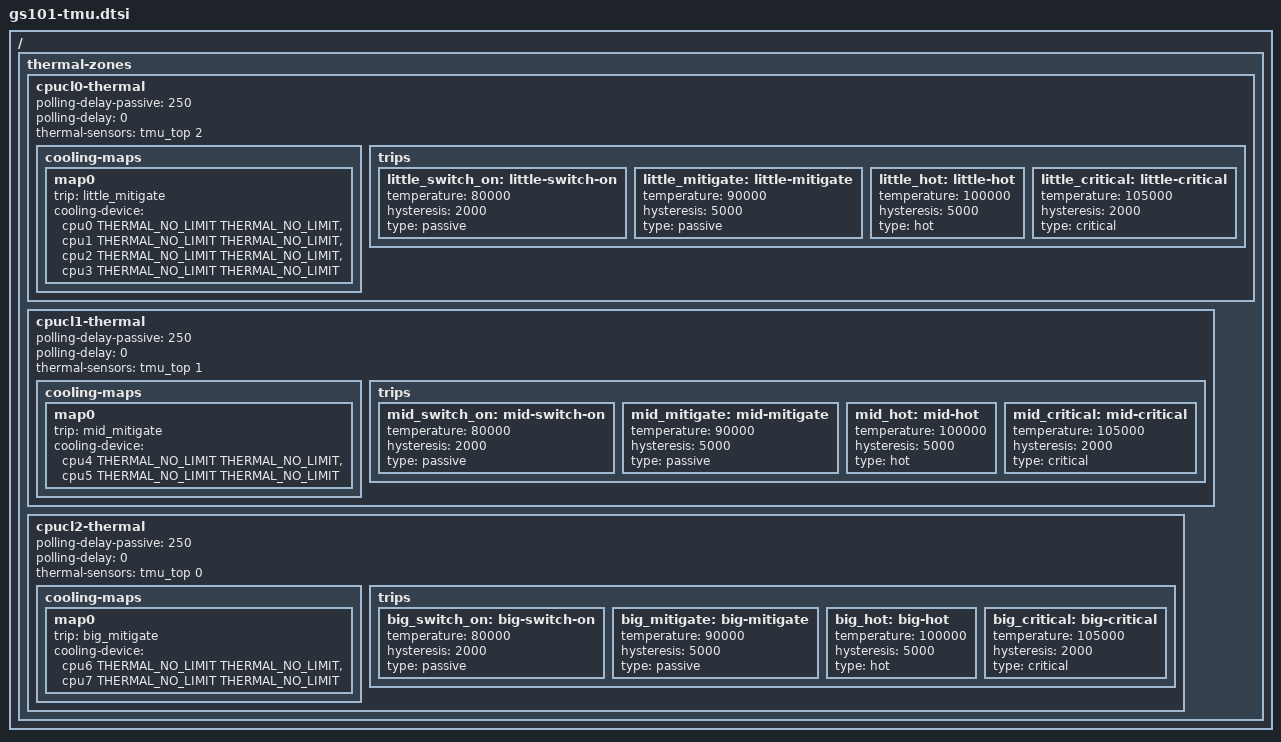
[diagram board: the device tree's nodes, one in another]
// SPDX-License-Identifier: GPL-2.0-only
/*
 * Google GS101 TMU configurations device tree source
 *
 * Copyright 2020 Samsung Electronics Co., Ltd.
 * Copyright 2020 Google LLC.
 * Copyright 2026 Linaro Ltd.
 */

#include <dt-bindings/thermal/thermal.h>

/ {
	thermal-zones {
		cpucl0-thermal {
			polling-delay-passive = <250>;
			polling-delay = <0>;
			thermal-sensors = <&tmu_top 2>;

			cooling-maps {
				map0 {
					trip = <&little_mitigate>;
					cooling-device = <&cpu0 THERMAL_NO_LIMIT THERMAL_NO_LIMIT>,
							 <&cpu1 THERMAL_NO_LIMIT THERMAL_NO_LIMIT>,
							 <&cpu2 THERMAL_NO_LIMIT THERMAL_NO_LIMIT>,
							 <&cpu3 THERMAL_NO_LIMIT THERMAL_NO_LIMIT>;
				};
			};

			trips {
				little_switch_on: little-switch-on {
					temperature = <80000>;
					hysteresis = <2000>;
					type = "passive";
				};

				little_mitigate: little-mitigate {
					temperature = <90000>;
					hysteresis = <5000>;
					type = "passive";
				};

				little_hot: little-hot {
					temperature = <100000>;
					hysteresis = <5000>;
					type = "hot";
				};

				little_critical: little-critical {
					temperature = <105000>;
					hysteresis = <2000>;
					type = "critical";
				};
			};
		};

		cpucl1-thermal {
			polling-delay-passive = <250>;
			polling-delay = <0>;
			thermal-sensors = <&tmu_top 1>;

			cooling-maps {
				map0 {
					trip = <&mid_mitigate>;
					cooling-device = <&cpu4 THERMAL_NO_LIMIT THERMAL_NO_LIMIT>,
							 <&cpu5 THERMAL_NO_LIMIT THERMAL_NO_LIMIT>;
				};
			};

			trips {
				mid_switch_on: mid-switch-on {
					temperature = <80000>;
					hysteresis = <2000>;
					type = "passive";
				};

				mid_mitigate: mid-mitigate {
					temperature = <90000>;
					hysteresis = <5000>;
					type = "passive";
				};

				mid_hot: mid-hot {
					temperature = <100000>;
					hysteresis = <5000>;
					type = "hot";
				};

				mid_critical: mid-critical {
					temperature = <105000>;
					hysteresis = <2000>;
					type = "critical";
				};
			};
		};

		cpucl2-thermal {
			polling-delay-passive = <250>;
			polling-delay = <0>;
			thermal-sensors = <&tmu_top 0>;

			cooling-maps {
				map0 {
					trip = <&big_mitigate>;
					cooling-device = <&cpu6 THERMAL_NO_LIMIT THERMAL_NO_LIMIT>,
							 <&cpu7 THERMAL_NO_LIMIT THERMAL_NO_LIMIT>;
				};
			};

			trips {
				big_switch_on: big-switch-on {
					temperature = <80000>;
					hysteresis = <2000>;
					type = "passive";
				};

				big_mitigate: big-mitigate {
					temperature = <90000>;
					hysteresis = <5000>;
					type = "passive";
				};

				big_hot: big-hot {
					temperature = <100000>;
					hysteresis = <5000>;
					type = "hot";
				};

				big_critical: big-critical {
					temperature = <105000>;
					hysteresis = <2000>;
					type = "critical";
				};
			};
		};
	};
};
